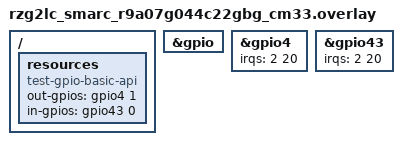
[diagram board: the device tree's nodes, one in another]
/*
 * Copyright (c) 2025 Renesas Electronics Corporation
 * SPDX-License-Identifier: Apache-2.0
 */

/ {
	resources {
		compatible = "test-gpio-basic-api";
		out-gpios = <&gpio4 1 GPIO_ACTIVE_HIGH>;
		in-gpios = <&gpio43 0 GPIO_ACTIVE_HIGH>;
	};
};

&gpio {
	status = "okay";
};

&gpio4 {
	irqs = <2 20>;
	status = "okay";
};

&gpio43 {
	irqs = <2 20>;
	status = "okay";
};
